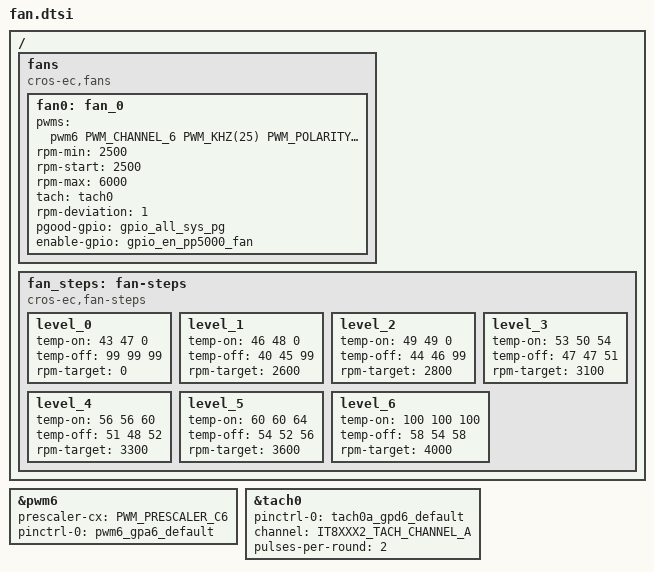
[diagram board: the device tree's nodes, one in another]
/* Copyright 2025 The ChromiumOS Authors
 * Use of this source code is governed by a BSD-style license that can be
 * found in the LICENSE file.
 */
/ {
	fans {
		compatible = "cros-ec,fans";

		fan0: fan_0 {
			pwms = <&pwm6 PWM_CHANNEL_6 PWM_KHZ(25) PWM_POLARITY_NORMAL>;
			rpm-min = <2500>;
			rpm-start = <2500>;
			rpm-max = <6000>;
			tach = <&tach0>;
			rpm-deviation = <1>;
			pgood-gpio = <&gpio_all_sys_pg>;
			enable-gpio = <&gpio_en_pp5000_fan>;
		};
	};

	fan_steps: fan-steps {
		compatible = "cros-ec,fan-steps";
		level_0 {
			temp-on = <43 47 0>;
			temp-off = <99 99 99>;
			rpm-target = <0>;
		};
		level_1 {
			temp-on = <46 48 0>;
			temp-off = <40 45 99>;
			rpm-target = <2600>;
		};
		level_2 {
			temp-on = <49 49 0>;
			temp-off = <44 46 99>;
			rpm-target = <2800>;
		};
		level_3 {
			temp-on = <53 50 54>;
			temp-off = <47 47 51>;
			rpm-target = <3100>;
		};
		level_4 {
			temp-on = <56 56 60>;
			temp-off = <51 48 52>;
			rpm-target = <3300>;
		};
		level_5 {
			temp-on = <60 60 64>;
			temp-off = <54 52 56>;
			rpm-target = <3600>;
		};
		level_6 {
			temp-on = <100 100 100>;
			temp-off = <58 54 58>;
			rpm-target = <4000>;
		};
	};
};

&pwm6 {
	status = "okay";
	prescaler-cx = <PWM_PRESCALER_C6>;
	pinctrl-0 = <&pwm6_gpa6_default>;
	pinctrl-names = "default";
};

&tach0 {
	status = "okay";
	pinctrl-0 = <&tach0a_gpd6_default>;
	pinctrl-names = "default";
	channel = <IT8XXX2_TACH_CHANNEL_A>;
	pulses-per-round = <2>;
};
